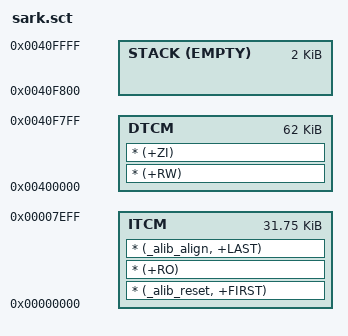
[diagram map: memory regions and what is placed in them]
#
# sark.sct	   armlink scatter file for SARK/SpiNNaker applications
#
# Copyright (C)    The University of Manchester - 2011
#
# Author           Steve Temple, APT Group, School of Computer Science
#
# Email            temples@cs.man.ac.uk
#

# Copyright (c) 2011-2019 The University of Manchester
#
# This program is free software: you can redistribute it and/or modify
# it under the terms of the GNU General Public License as published by
# the Free Software Foundation, either version 3 of the License, or
# (at your option) any later version.
#
# This program is distributed in the hope that it will be useful,
# but WITHOUT ANY WARRANTY; without even the implied warranty of
# MERCHANTABILITY or FITNESS FOR A PARTICULAR PURPOSE.  See the
# GNU General Public License for more details.
#
# You should have received a copy of the GNU General Public License
# along with this program.  If not, see <http://www.gnu.org/licenses/>.


IMAGE 0
{
      	ITCM 0 0x7f00
  	{
    	    	* (_alib_reset, +FIRST)
    		* (+RO)
		* (_alib_align, +LAST)
  	}

  	DTCM 0x400000 0xf800
  	{
    		* (+RW)
		* (+ZI)
  	}

	STACK 0x40f800 EMPTY 0x800
	{
	}
}
